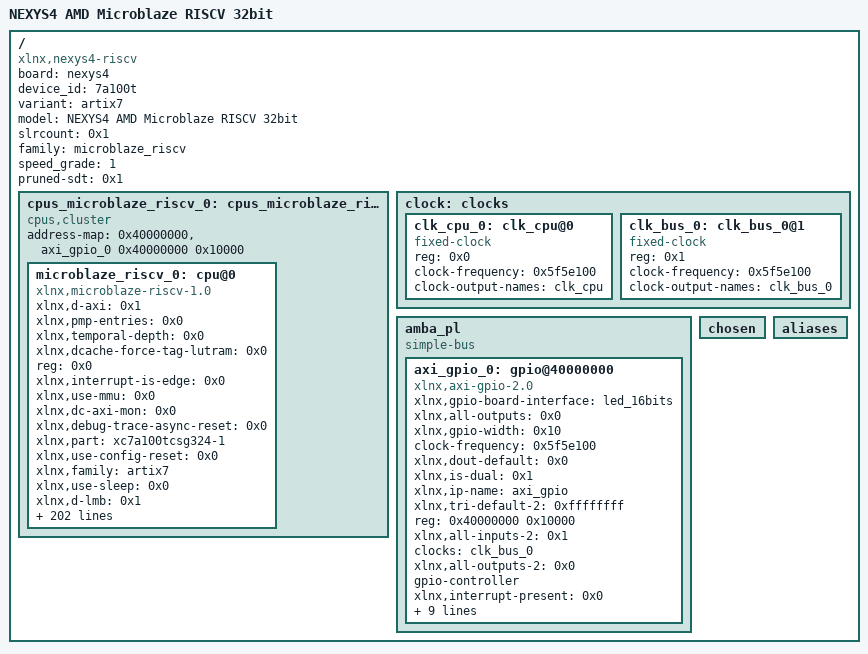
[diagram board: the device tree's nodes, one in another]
/dts-v1/;
/ {
        board = "nexys4";
        compatible = "xlnx,nexys4-riscv", "qemu,mbv", "amd,mbv";
        device_id = "7a100t";
        #address-cells = <0x1>;
        variant = "artix7";
        model = "NEXYS4 AMD Microblaze RISCV 32bit";
        #size-cells = <0x1>;
        slrcount = <0x1>;
        family = "microblaze_riscv";
        speed_grade = "1";
        pruned-sdt = <0x1>;

        cpus_microblaze_riscv_0: cpus_microblaze_riscv@0 {
                phandle = <0x5>;
                #cpu-mask-cells = <0x1>;
                compatible = "cpus,cluster";
                #address-cells = <0x1>;
                bootph-all;
                #size-cells = <0x0>;
                address-map = <0x40000000 &axi_gpio_0 0x40000000 0x10000>;
                #ranges-address-cells = <0x1>;
                #ranges-size-cells = <0x1>;

                microblaze_riscv_0: cpu@0 {
                        phandle = <0x6>;
                        xlnx,d-axi = <0x1>;
                        xlnx,pmp-entries = <0x0>;
                        xlnx,temporal-depth = <0x0>;
                        xlnx,dcache-force-tag-lutram = <0x0>;
                        reg = <0x0>;
                        xlnx,interrupt-is-edge = <0x0>;
                        xlnx,use-mmu = <0x0>;
                        xlnx,dc-axi-mon = <0x0>;
                        xlnx,debug-trace-async-reset = <0x0>;
                        xlnx,part = "xc7a100tcsg324-1";
                        xlnx,use-config-reset = <0x0>;
                        xlnx,family = "artix7";
                        xlnx,use-sleep = <0x0>;
                        xlnx,d-lmb = <0x1>;
                        xlnx,enable-discrete-ports = <0x0>;
                        xlnx,debug-interface = <0x0>;
                        xlnx,use-ext-brk = <0x0>;
                        xlnx,debug-enabled = <0x1>;
                        xlnx,daddr-size = <0x20>;
                        xlnx,use-extended-fsl-instr = <0x0>;
                        xlnx,branch-target-cache-size = <0x0>;
                        bus-handle = <&amba_pl>;
                        xlnx,pmp-addr0 = <0x0>;
                        xlnx,pmp-addr1 = <0x0>;
                        xlnx,pmp-addr2 = <0x0>;
                        xlnx,pmp-addr3 = <0x0>;
                        xlnx,pmp-addr4 = <0x0>;
                        xlnx,edk-special = "microblaze_riscv";
                        xlnx,use-dcache = <0x0>;
                        xlnx,pmp-addr5 = <0x0>;
                        xlnx,use-muldiv = <0x0>;
                        xlnx,pmp-addr6 = <0x0>;
                        xlnx,use-axi-dp-ext-addr = <0x0>;
                        xlnx,pmp-addr7 = <0x0>;
                        xlnx,pmp-addr8 = <0x0>;
                        xlnx,pmp-addr9 = <0x0>;
                        xlnx,i-axi = <0x0>;
                        xlnx,icache-streams = <0x0>;
                        xlnx,i-lmb-has-prot = <0x0>;
                        xlnx,num-sync-ff-dbg-clk = <0x1>;
                        xlnx,icache-byte-size = <0x2000>;
                        xlnx,pmp-addr10 = <0x0>;
                        d-cache-size = <0x2000>;
                        xlnx,pmp-addr11 = <0x0>;
                        xlnx,pmp-addr12 = <0x0>;
                        xlnx,pmp-addr13 = <0x0>;
                        xlnx,pmp-addr14 = <0x0>;
                        xlnx,pmp-addr15 = <0x0>;
                        bootph-all;
                        xlnx,avoid-primitives = <0x0>;
                        xlnx,pmp-addr16 = <0x0>;
                        xlnx,pmp-addr17 = <0x0>;
                        xlnx,pmp-addr18 = <0x0>;
                        xlnx,pdaddr-size = <0x20>;
                        xlnx,pmp-addr19 = <0x0>;
                        xlnx,pmp-addr20 = <0x0>;
                        xlnx,pmp-addr21 = <0x0>;
                        xlnx,i-lmb = <0x1>;
                        xlnx,pmp-addr22 = <0x0>;
                        xlnx,lmb-data-size = <0x20>;
                        xlnx,lockstep-select = <0x0>;
                        xlnx,pmp-addr23 = <0x0>;
                        timebase-frequency = <0x5f5e100>;
                        xlnx,pmp-addr24 = <0x0>;
                        xlnx,dcache-data-width = <0x0>;
                        xlnx,icache-force-tag-lutram = <0x0>;
                        xlnx,pmp-addr25 = <0x0>;
                        xlnx,use-branch-target-cache = <0x0>;
                        xlnx,pmp-addr26 = <0x0>;
                        xlnx,pmp-addr27 = <0x0>;
                        xlnx,number-of-pc-brk = <0x1>;
                        xlnx,pmp-addr28 = <0x0>;
                        xlnx,imprecise-exceptions = <0x0>;
                        xlnx,pmp-addr29 = <0x0>;
                        xlnx,pmp-addr30 = <0x0>;
                        xlnx,pmp-addr31 = <0x0>;
                        xlnx,pmp-addr32 = <0x0>;
                        model = "microblaze_riscv,1.0";
                        xlnx,pmp-addr33 = <0x0>;
                        xlnx,pmp-addr34 = <0x0>;
                        xlnx,pmp-addr35 = <0x0>;
                        xlnx,pmp-addr36 = <0x0>;
                        d-cache-highaddr = <0x3fffffff>;
                        xlnx,optimization = <0x2>;
                        xlnx,pmp-addr37 = <0x0>;
                        xlnx,pmp-addr38 = <0x0>;
                        xlnx,pmp-addr39 = <0x0>;
                        xlnx,pmp-addr40 = <0x0>;
                        xlnx,pmp-addr41 = <0x0>;
                        xlnx,d-lmb-mon = <0x0>;
                        xlnx,pmp-addr42 = <0x0>;
                        xlnx,pmp-addr43 = <0x0>;
                        xlnx,pmp-addr44 = <0x0>;
                        xlnx,pmp-addr45 = <0x0>;
                        xlnx,pmp-addr46 = <0x0>;
                        xlnx,pmp-addr47 = <0x0>;
                        xlnx,pmp-addr48 = <0x0>;
                        xlnx,fault-tolerant = <0x0>;
                        xlnx,pmp-addr49 = <0x0>;
                        xlnx,pmp-addr50 = <0x0>;
                        xlnx,pmp-addr51 = <0x0>;
                        xlnx,pmp-enhancements = <0x0>;
                        d-cache-line-size = <0x10>;
                        xlnx,mmu-privileged-instr = <0x0>;
                        xlnx,pmp-addr52 = <0x0>;
                        clock-frequency = <0x5f5e100>;
                        xlnx,pmp-addr53 = <0x0>;
                        xlnx,pmp-addr54 = <0x0>;
                        xlnx,pmp-addr55 = <0x0>;
                        xlnx,i-lmb-protocol = <0x0>;
                        xlnx,pmp-addr56 = <0x0>;
                        xlnx,pmp-addr57 = <0x0>;
                        riscv,isa = "rv32ia";
                        xlnx,dp-axi-mon = <0x0>;
                        xlnx,pmp-addr58 = <0x0>;
                        xlnx,pmp-addr59 = <0x0>;
                        xlnx,pmp-addr60 = <0x0>;
                        xlnx,pmp-addr61 = <0x0>;
                        xlnx,pmp-addr62 = <0x0>;
                        xlnx,pmp-addr63 = <0x0>;
                        xlnx,debug-external-trace = <0x0>;
                        xlnx,addr-size = <0x20>;
                        xlnx,debug-num-progbuf = <0x2>;
                        xlnx,debug-event-counters = <0x0>;
                        xlnx,edk-iptype = "PROCESSOR";
                        xlnx,debug-latency-counters = <0x0>;
                        xlnx,interconnect = <0x2>;
                        xlnx,edge-is-positive = <0x1>;
                        xlnx,use-icache = <0x0>;
                        xlnx,async-wakeup = <0x3>;
                        xlnx,s-axi = <0x0>;
                        xlnx,use-ext-nm-brk = <0x0>;
                        xlnx,ic-axi-mon = <0x0>;
                        xlnx,archid = <0x1>;
                        xlnx,num-sync-ff-clk-irq = <0x1>;
                        xlnx,freq = <0x5f5e100>;
                        xlnx,lockstep-master = <0x0>;
                        xlnx,pmp-cfg0 = <0x0>;
                        xlnx,pmp-cfg1 = <0x0>;
                        xlnx,iaddr-size = <0x20>;
                        xlnx,interrupt-mon = <0x0>;
                        xlnx,pmp-cfg2 = <0x0>;
                        xlnx,number-of-wr-addr-brk = <0x0>;
                        xlnx,pmp-cfg3 = <0x0>;
                        xlnx,pmp-cfg4 = <0x0>;
                        xlnx,use-interrupt = <0x0>;
                        xlnx,pmp-cfg5 = <0x0>;
                        xlnx,async-interrupt = <0x1>;
                        xlnx,pc-width = <0x20>;
                        xlnx,pmp-cfg6 = <0x0>;
                        xlnx,icache-victims = <0x0>;
                        xlnx,pmp-cfg7 = <0x0>;
                        xlnx,pmp-cfg8 = <0x0>;
                        xlnx,pmp-cfg9 = <0x0>;
                        xlnx,use-bitman-a = <0x0>;
                        xlnx,use-bitman-b = <0x0>;
                        xlnx,use-bitman-c = <0x0>;
                        i-cache-baseaddr = <0x0>;
                        xlnx,i-lmb-mon = <0x0>;
                        xlnx,dcache-byte-size = <0x2000>;
                        xlnx,data-size = <0x20>;
                        compatible = "xlnx,microblaze-riscv-1.0", "amd,mbv32", "riscv", "xlnx,microblaze_riscv";
                        xlnx,pmp-debug-inhibit = <0x0>;
                        xlnx,use-sstc = <0x1>;
                        xlnx,fsl-exception = <0x0>;
                        riscv,isa-base = "rv32i";
                        xlnx,dcache-use-writeback = <0x0>;
                        device_type = "cpu";
                        xlnx,impid = <0x1>;
                        xlnx,use-bitman-s = <0x0>;
                        xlnx,base-vectors = <0x0>;
                        xlnx,icache-line-len = <0x4>;
                        xlnx,d-lmb-has-prot = <0x0>;
                        xlnx,use-barrel = <0x1>;
                        xlnx,misaligned-exceptions = <0x1>;
                        xlnx,piaddr-size = <0x20>;
                        xlnx,use-bitman = <0x0>;
                        riscv,isa-extensions = "i", "a", "zicsr", "zifencei", "zicntr";
                        xlnx,dcache-line-len = <0x4>;
                        xlnx,num-sync-ff-clk = <0x2>;
                        i-cache-size = <0x2000>;
                        xlnx,number-of-rd-addr-brk = <0x0>;
                        xlnx,use-counters = <0x1>;
                        xlnx,lockstep-slave = <0x0>;
                        xlnx,pmp-cfg10 = <0x0>;
                        xlnx,pmp-cfg11 = <0x0>;
                        xlnx,debug-profile-size = <0x0>;
                        xlnx,pmp-cfg12 = <0x0>;
                        xlnx,pmp-cfg13 = <0x0>;
                        xlnx,pmp-cfg14 = <0x0>;
                        xlnx,pmp-cfg15 = <0x0>;
                        xlnx,debug-counter-width = <0x40>;
                        xlnx,icache-data-width = <0x0>;
                        xlnx,ip-name = "microblaze_riscv";
                        xlnx,ip-axi-mon = <0x0>;
                        xlnx,d-lmb-protocol = <0x0>;
                        xlnx,trace = <0x0>;
                        xlnx,ill-instr-exception = <0x2>;
                        xlnx,debug-trace-size = <0x0>;
                        xlnx,pmp-granularity = <0x2>;
                        xlnx,num-sync-ff-dbg-trace-clk = <0x2>;
                        i-cache-line-size = <0x10>;
                        xlnx,ecc-use-ce-exception = <0x0>;
                        i-cache-highaddr = <0x3fffffff>;
                        xlnx,num-sync-ff-clk-debug = <0x2>;
                        xlnx,use-atomic = <0x1>;
                        clocks = <&clk_cpu_0>;
                        xlnx,g-template-list = <0x0>;
                        xlnx,trap-enhancement = <0x0>;
                        xlnx,hartid = <0x0>;
                        xlnx,use-fpu = <0x0>;
                        xlnx,use-non-secure = <0x0>;
                        d-cache-baseaddr = <0x0>;
                        xlnx,use-compression = <0x0>;
                        xlnx,instr-size = <0x20>;
                        xlnx,fsl-links = <0x0>;
                        xlnx,dcache-victims = <0x0>;
                        xlnx,pmp-read-only = <0x0>;
                };
        };

        clock: clocks {
                phandle = <0x7>;
                #address-cells = <0x1>;
                #size-cells = <0x0>;

                clk_cpu_0: clk_cpu@0 {
                        phandle = <0x3>;
                        compatible = "fixed-clock";
                        bootph-all;
                        reg = <0x0>;
                        clock-frequency = <0x5f5e100>;
                        clock-output-names = "clk_cpu";
                        #clock-cells = <0x0>;
                };

                clk_bus_0: clk_bus_0@1 {
                        phandle = <0x4>;
                        compatible = "fixed-clock";
                        bootph-all;
                        reg = <0x1>;
                        clock-frequency = <0x5f5e100>;
                        clock-output-names = "clk_bus_0";
                        #clock-cells = <0x0>;
                };
        };

        amba_pl: amba_pl {
                phandle = <0x2>;
                ranges;
                compatible = "simple-bus";
                #address-cells = <0x1>;
                bootph-all;
                #size-cells = <0x1>;

                axi_gpio_0: gpio@40000000 {
                        phandle = <0x1>;
                        xlnx,gpio-board-interface = "led_16bits";
                        compatible = "xlnx,axi-gpio-2.0", "xlnx,xps-gpio-1.00.a";
                        xlnx,all-outputs = <0x0>;
                        #gpio-cells = <0x2>;
                        xlnx,gpio-width = <0x10>;
                        clock-frequency = <0x5f5e100>;
                        xlnx,dout-default = <0x0>;
                        xlnx,is-dual = <0x1>;
                        xlnx,ip-name = "axi_gpio";
                        xlnx,tri-default-2 = <0xffffffff>;
                        reg = <0x40000000 0x10000>;
                        xlnx,all-inputs-2 = <0x1>;
                        clocks = <&clk_bus_0>;
                        xlnx,all-outputs-2 = <0x0>;
                        gpio-controller;
                        device_type = "gpio";
                        xlnx,interrupt-present = <0x0>;
                        xlnx,gpio2-board-interface = "dip_switches_16bits";
                        xlnx,edk-iptype = "PERIPHERAL";
                        xlnx,dout-default-2 = <0x0>;
                        status = "okay";
                        xlnx,gpio2-width = <0x10>;
                        clock-names = "s_axi_aclk";
                        xlnx,use-board-flow;
                        xlnx,tri-default = <0xffffffff>;
                        xlnx,name = "axi_gpio_0";
                        xlnx,all-inputs = <0x0>;
                };
        };

        chosen {
        };

        aliases {
        };

        __symbols__ {
                cpus_microblaze_riscv_0 = "/cpus_microblaze_riscv@0";
                microblaze_riscv_0 = "/cpus_microblaze_riscv@0/cpu@0";
                clock = "/clocks";
                clk_cpu_0 = "/clocks/clk_cpu@0";
                clk_bus_0 = "/clocks/clk_bus_0@1";
                amba_pl = "/amba_pl";
                axi_gpio_0 = "/amba_pl/gpio@40000000";
        };
};
